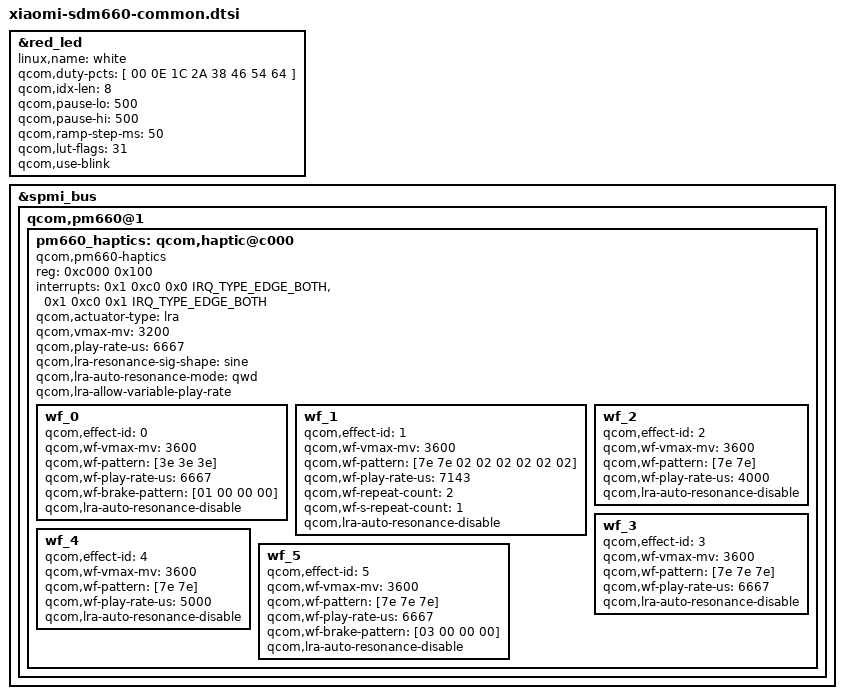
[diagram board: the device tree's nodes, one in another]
/* Red led was used for powersupply of White led */
&red_led {
	linux,name = "white";
	qcom,duty-pcts = [ 00 0E 1C 2A 38 46 54 64 ];
	qcom,idx-len = <8>;
	qcom,pause-lo = <500>;
	qcom,pause-hi = <500>;
	qcom,ramp-step-ms = <50>;
	qcom,lut-flags = <31>; /* loop, ramp up, reverse, pause hi, pause lo */
	qcom,use-blink;
};

&spmi_bus {
	qcom,pm660@1 {
		/delete-node/ qcom,haptics@c000;
		pm660_haptics: qcom,haptic@c000 {
			compatible = "qcom,pm660-haptics";
			reg = <0xc000 0x100>;
			interrupts = <0x1 0xc0 0x0 IRQ_TYPE_EDGE_BOTH>,
				     <0x1 0xc0 0x1 IRQ_TYPE_EDGE_BOTH>;
			interrupt-names = "hap-sc-irq", "hap-play-irq";
			qcom,actuator-type = "lra";
			qcom,vmax-mv = <3200>;
			qcom,play-rate-us = <6667>;
			qcom,lra-resonance-sig-shape = "sine";
			qcom,lra-auto-resonance-mode = "qwd";
			qcom,lra-allow-variable-play-rate;

			wf_0 {
				/* CLICK */
				qcom,effect-id = <0>;
				qcom,wf-vmax-mv = <3600>;
				qcom,wf-pattern = [3e 3e 3e];
				qcom,wf-play-rate-us = <6667>;
				qcom,wf-brake-pattern = [01 00 00 00];
				qcom,lra-auto-resonance-disable;
			};
			wf_1 {
				/* DOUBLE CLICK */
				qcom,effect-id = <1>;
				qcom,wf-vmax-mv = <3600>;
				qcom,wf-pattern = [7e 7e 02 02 02 02 02 02];
				qcom,wf-play-rate-us = <7143>;
				qcom,wf-repeat-count = <2>;
				qcom,wf-s-repeat-count = <1>;
				qcom,lra-auto-resonance-disable;
			};
			wf_2 {
				/* TICK */
				qcom,effect-id = <2>;
				qcom,wf-vmax-mv = <3600>;
				qcom,wf-pattern = [7e 7e];
				qcom,wf-play-rate-us = <4000>;
				qcom,lra-auto-resonance-disable;
			};
			wf_3 {
				/* THUD */
				qcom,effect-id = <3>;
				qcom,wf-vmax-mv = <3600>;
				qcom,wf-pattern = [7e 7e 7e];
				qcom,wf-play-rate-us = <6667>;
				qcom,lra-auto-resonance-disable;
			};
			wf_4 {
				/* POP */
				qcom,effect-id = <4>;
				qcom,wf-vmax-mv = <3600>;
				qcom,wf-pattern = [7e 7e];
				qcom,wf-play-rate-us = <5000>;
				qcom,lra-auto-resonance-disable;
			};
			wf_5 {
				/* HEAVY CLICK */
				qcom,effect-id = <5>;
				qcom,wf-vmax-mv = <3600>;
				qcom,wf-pattern = [7e 7e 7e];
				qcom,wf-play-rate-us = <6667>;
				qcom,wf-brake-pattern = [03 00 00 00];
				qcom,lra-auto-resonance-disable;
			};
		};
	};
};
